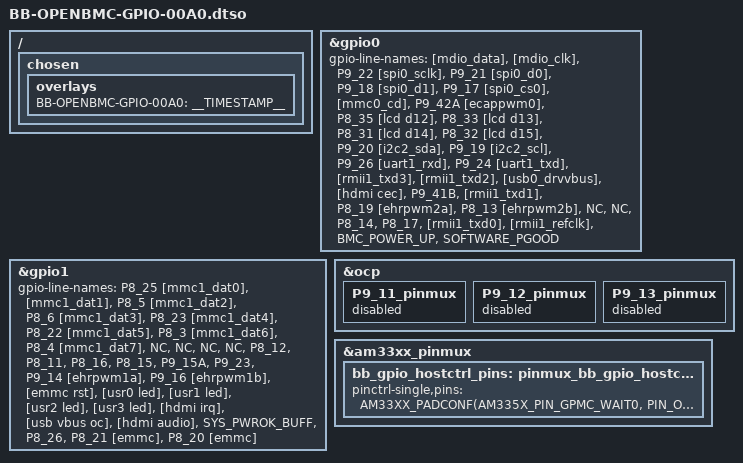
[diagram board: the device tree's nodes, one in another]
// SPDX-License-Identifier: GPL-2.0-only
/*
 * Copyright (C) 2024 Ryan Agius <ryagius17@gmail.com>
 * Virtual cape for GPIO host control support for OpenBMC
 */

/dts-v1/;
/plugin/;

#include <dt-bindings/pinctrl/am33xx.h>
#include <dt-bindings/gpio/gpio.h>

/ {
	/*
	 * Helper to show loaded overlays under: /proc/device-tree/chosen/overlays/
	 */
	fragment@0 {
		target-path="/";
		__overlay__ {

			chosen {
				overlays {
					BB-OPENBMC-GPIO-00A0 = __TIMESTAMP__;
				};
			};
		};
	};

	/*
	 * Rename pins
	 */
	fragment@1 {
		target = <&gpio0>;
		__overlay__ {
			gpio-line-names =
				"[mdio_data]",
				"[mdio_clk]",
				"P9_22 [spi0_sclk]",
				"P9_21 [spi0_d0]",
				"P9_18 [spi0_d1]",
				"P9_17 [spi0_cs0]",
				"[mmc0_cd]",
				"P9_42A [ecappwm0]",
				"P8_35 [lcd d12]",
				"P8_33 [lcd d13]",
				"P8_31 [lcd d14]",
				"P8_32 [lcd d15]",
				"P9_20 [i2c2_sda]",
				"P9_19 [i2c2_scl]",
				"P9_26 [uart1_rxd]",
				"P9_24 [uart1_txd]",
				"[rmii1_txd3]",
				"[rmii1_txd2]",
				"[usb0_drvvbus]",
				"[hdmi cec]",
				"P9_41B",
				"[rmii1_txd1]",
				"P8_19 [ehrpwm2a]",
				"P8_13 [ehrpwm2b]",
				"NC",
				"NC",
				"P8_14",
				"P8_17",
				"[rmii1_txd0]",
				"[rmii1_refclk]",
				"BMC_POWER_UP",
				"SOFTWARE_PGOOD";
		};
	};

	/*
	 * Rename pins
	 */
	 fragment@2 {
		target = <&gpio1>;
		__overlay__ {
			gpio-line-names =
				"P8_25 [mmc1_dat0]",
				"[mmc1_dat1]",
				"P8_5 [mmc1_dat2]",
				"P8_6 [mmc1_dat3]",
				"P8_23 [mmc1_dat4]",
				"P8_22 [mmc1_dat5]",
				"P8_3 [mmc1_dat6]",
				"P8_4 [mmc1_dat7]",
				"NC",
				"NC",
				"NC",
				"NC",
				"P8_12",
				"P8_11",
				"P8_16",
				"P8_15",
				"P9_15A",
				"P9_23",
				"P9_14 [ehrpwm1a]",
				"P9_16 [ehrpwm1b]",
				"[emmc rst]",
				"[usr0 led]",
				"[usr1 led]",
				"[usr2 led]",
				"[usr3 led]",
				"[hdmi irq]",
				"[usb vbus oc]",
				"[hdmi audio]",
				"SYS_PWROK_BUFF",
				"P8_26",
				"P8_21 [emmc]",
				"P8_20 [emmc]";
		};
	};

	/*
	 * Free pinx from pinmux helpers
	 */
	fragment@3 {
		target = <&ocp>;
		__overlay__ {
          P9_11_pinmux { status = "disabled"; };	/* P9_11: uart4_rxd */
					P9_12_pinmux { status = "disabled"; };	/* P9_12: */
	        P9_13_pinmux { status = "disabled"; };	/* P9_13: uart4_txd */
		};
	};

	fragment@4 {
		target = <&am33xx_pinmux>;
		__overlay__ {
			bb_gpio_hostctrl_pins: pinmux_bb_gpio_hostctrl_pins {
				pinctrl-single,pins = <
			    AM33XX_PADCONF(AM335X_PIN_GPMC_WAIT0, PIN_OUTPUT_PULLDOWN, MUX_MODE7)	/* P9_11 gpmc_wait0.uart4_rxd_mux2 */
					AM33XX_PADCONF(AM335X_PIN_GPMC_BEN1, PIN_INPUT_PULLUP, MUX_MODE7) /* P9_12 */
          AM33XX_PADCONF(AM335X_PIN_GPMC_WPN, PIN_OUTPUT_PULLDOWN, MUX_MODE7)	/* P9_13 gpmc_wpn.uart4_txd_mux2 */
				>;
			};
		};
	};

};
